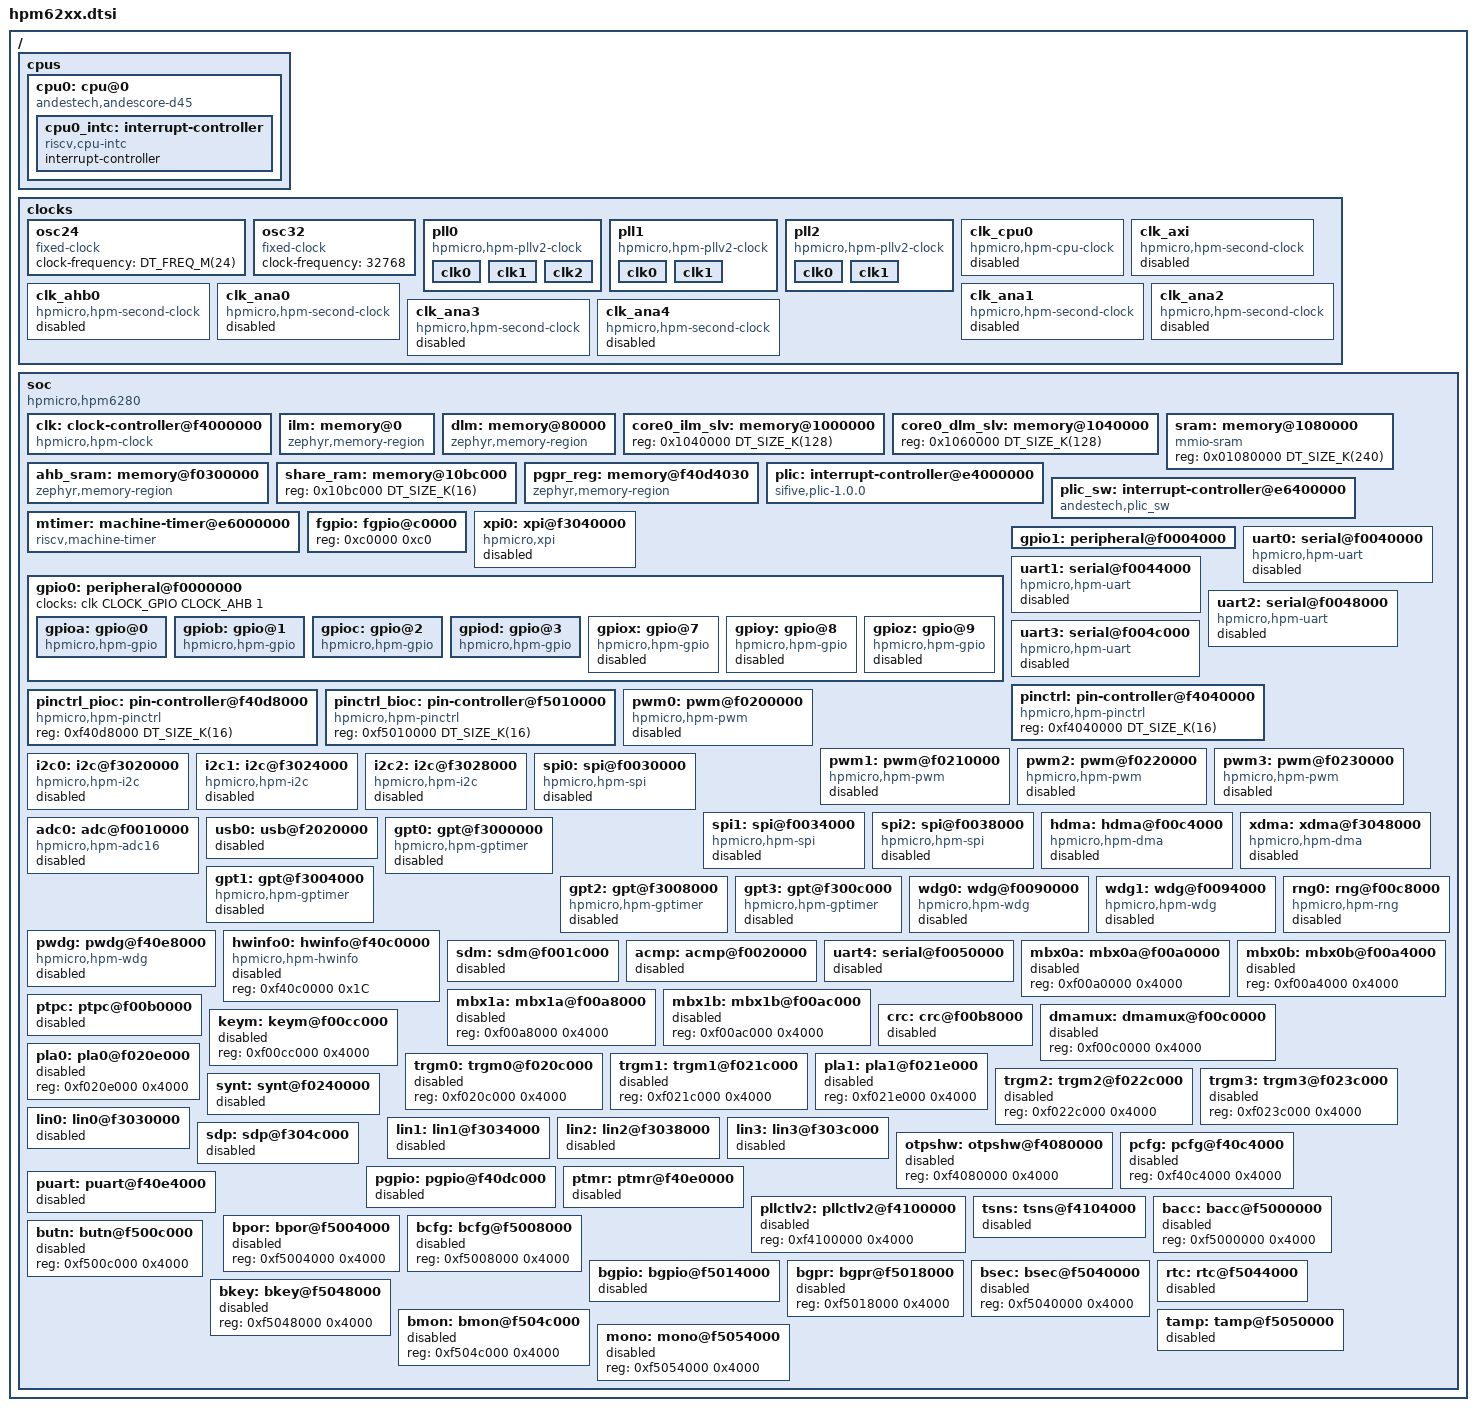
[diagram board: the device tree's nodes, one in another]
/*
* Copyright 2023-2026 HPMicro
* SPDX-License-Identifier: Apache-2.0
*/

/dts-v1/;
#include <zephyr/dt-bindings/gpio/gpio.h>
#include <zephyr/dt-bindings/i2c/i2c.h>
#include <zephyr/dt-bindings/pwm/pwm.h>
#include <dt-bindings/pwm/hpmicro-pwm-common.h>
#include <mem.h>
#include <freq.h>

/ {
	#address-cells = <1>;
	#size-cells = <1>;
	cpus {
		#address-cells = <1>;
		#size-cells = <0>;
		cpu0: cpu@0 {
			compatible = "andestech,andescore-d45", "riscv";
			reg = <0>;
			status = "okay";
			riscv,isa-base = "rv32i";
			riscv,isa-extensions = "i", "m", "a", "c", "f", "d", "b", "p", "zicsr", "zifencei",
				"xandes";
			i-cache-line-size = <64>;
			d-cache-line-size = <64>;
			cpu0_intc: interrupt-controller {
				compatible = "riscv,cpu-intc";
				#address-cells = <0>;
				#interrupt-cells = <1>;
				interrupt-controller;
			};
		};
	};

	clocks {
		osc24: osc24 {
			#clock-cells = <0>;
			compatible = "fixed-clock";
			clock-frequency = <DT_FREQ_M(24)>;
		};

		osc32: osc32 {
			#clock-cells = <0>;
			compatible = "fixed-clock";
			clock-frequency = <32768>;
		};

		pll0: pll0 {
			#clock-cells = <2>;
			compatible = "hpmicro,hpm-pllv2-clock";
			pll-frequency = <DT_FREQ_M(400)>;
			pll-index = <0>;
			clk0 {
				src-name = <CLK_SRC_PLL0_CLK0>;
				div-i = <0>;
				div-p = <0>;
			};

			clk1 {
				src-name = <CLK_SRC_PLL0_CLK1>;
				div-i = <1>;
				div-p = <1>;
			};

			clk2 {
				src-name = <CLK_SRC_PLL0_CLK2>;
				div-i = <2>;
				div-p = <3>;
			};
		};

		pll1: pll1 {
			#clock-cells = <2>;
			compatible = "hpmicro,hpm-pllv2-clock";
			pll-frequency = <DT_FREQ_M(576)>;
			pll-index = <1>;
			clk0 {
				src-name = <CLK_SRC_PLL1_CLK0>;
				div-i = <0>;
				div-p = <1>;
			};

			clk1 {
				src-name = <CLK_SRC_PLL1_CLK1>;
				div-i = <1>;
				div-p = <4>;
			};
		};

		pll2: pll2 {
			#clock-cells = <2>;
			compatible = "hpmicro,hpm-pllv2-clock";
			pll-frequency = <722534400>;
			pll-index = <2>;
			clk0 {
				src-name = <CLK_SRC_PLL2_CLK0>;
				div-i = <0>;
				div-p = <2>;
			};

			clk1 {
				src-name = <CLK_SRC_PLL2_CLK1>;
				div-i = <1>;
				div-p = <3>;
			};
		};

		clk_cpu0: clk_cpu0 {
			#clock-cells = <0>;
			compatible = "hpmicro,hpm-cpu-clock";
			node-name = <CLOCK_CPU0>;
			clocks = <&pll0 0 1>;
			axi-divider = <2>;
			ahb-divider = <2>;
			status = "disabled";
		};

		clk_axi: clk_axi {
			#clock-cells = <0>;
			compatible = "hpmicro,hpm-second-clock";
			node-name = <CLOCK_AXI>;
			clocks = <&clk_cpu0>;
			status = "disabled";
		};

		clk_ahb0: clk_ahb0 {
			#clock-cells = <0>;
			compatible = "hpmicro,hpm-second-clock";
			node-name = <CLOCK_AHB>;
			clocks = <&clk_cpu0>;
			status = "disabled";
		};

		clk_ana0: clk_ana0 {
			#clock-cells = <0>;
			compatible = "hpmicro,hpm-second-clock";
			node-name = <CLOCK_ANA0>;
			clocks = <&pll0 0 2>;
			status = "disabled";
		};

		clk_ana1: clk_ana1 {
			#clock-cells = <0>;
			compatible = "hpmicro,hpm-second-clock";
			node-name = <CLOCK_ANA1>;
			clocks = <&pll0 0 2>;
			status = "disabled";
		};

		clk_ana2: clk_ana2 {
			#clock-cells = <0>;
			compatible = "hpmicro,hpm-second-clock";
			node-name = <CLOCK_ANA2>;
			clocks = <&pll0 0 2>;
			status = "disabled";
		};

		clk_ana3: clk_ana3 {
			#clock-cells = <0>;
			compatible = "hpmicro,hpm-second-clock";
			node-name = <CLOCK_ANA3>;
			clocks = <&pll0 0 2>;
			status = "disabled";
		};

		clk_ana4: clk_ana4 {
			#clock-cells = <0>;
			compatible = "hpmicro,hpm-second-clock";
			node-name = <CLOCK_ANA4>;
			clocks = <&pll0 0 2>;
			status = "disabled";
		};
	};

	soc {
		#address-cells = <1>;
		#size-cells = <1>;
		compatible = "hpmicro,hpm6280";
		ranges;
		clk: clock-controller@f4000000 {
			compatible = "hpmicro,hpm-clock";
			reg = <0xf4000000 DT_SIZE_K(256)
				0xf4100000 DT_SIZE_K(16)>;
			reg-names = "sysctl", "pllv2";
			status = "okay";
			#clock-cells = <3>;
		};

		ilm: memory@0 {
			compatible = "zephyr,memory-region";
			reg = <0x0 DT_SIZE_K(128)>;
			zephyr,memory-region = "ITCM";
		};

		dlm: memory@80000 {
			compatible = "zephyr,memory-region";
			reg = <0x080000 DT_SIZE_K(128)>;
			zephyr,memory-region = "DTCM";
		};

		core0_ilm_slv: memory@1000000 {
			reg = <0x1040000 DT_SIZE_K(128)>;
		};

		core0_dlm_slv: memory@1040000 {
			reg = <0x1060000 DT_SIZE_K(128)>;
		};

		sram: memory@1080000 {
			compatible = "mmio-sram";
			reg = <0x01080000 DT_SIZE_K(240)>;
		};

		ahb_sram: memory@f0300000 {
			compatible = "zephyr,memory-region";
			reg = <0xf0300000 DT_SIZE_K(32)>;
			zephyr,memory-region = "AHB_SRAM";
		};

		share_ram: memory@10bc000 {
			reg = <0x10bc000 DT_SIZE_K(16)>;
		};

		pgpr_reg: memory@f40d4030 {
			compatible = "zephyr,memory-region";
			reg = <0xf40d4030 16>;
			zephyr,memory-region = "PGPR_REG";
		};

		plic: interrupt-controller@e4000000 {
			compatible = "sifive,plic-1.0.0";
			#address-cells = <1>;
			#interrupt-cells = <2>;
			interrupt-controller;
			reg = <    0xe4000000 0x00001000
				0xe4002000 0x00000800
				0xe4200000 0x00010000 >;
			reg-names = "prio", "irq_en", "reg";
			riscv,max-priority = <7>;
			riscv,ndev = <94>;
			interrupts-extended = <&cpu0_intc 11>;
		};

		plic_sw: interrupt-controller@e6400000 {
			compatible = "andestech,plic_sw";
			#address-cells = <1>;
			#interrupt-cells = <2>;
			interrupt-controller;
			reg = <0xe6400000 0x00400000>;
			interrupts-extended = <&cpu0_intc 3>;
		};

		mtimer: machine-timer@e6000000 {
			compatible = "riscv,machine-timer";
			clocks = <&clk CLOCK_MCHTMR0 CLK_SRC_OSC24M 1>;
			reg = <0xe6000000 0x8
				0xe6000008 0x8>;
			reg-names = "mtime", "mtimecmp";
			interrupts-extended = <&cpu0_intc 7>;
		};

		fgpio: fgpio@c0000 {
			reg = <0xc0000 0xc0>;
		};

		xpi0: xpi@f3040000 {
			compatible = "hpmicro,xpi";
			reg = <0xf3040000 DT_SIZE_K(16)>;
			clocks = <&clk CLOCK_XPI0 CLK_SRC_PLL0_CLK1 2>;
			#address-cells = <1>;
			#size-cells = <1>;
			status = "disabled";
		};

		gpio0: peripheral@f0000000 {
			#address-cells = <1>;
			#size-cells = <1>;
			ranges = <0x0 0xf0000000 DT_SIZE_K(16)>;
			clocks = <&clk CLOCK_GPIO CLOCK_AHB 1>;
		};

		gpio1: peripheral@f0004000 {
			#address-cells = <1>;
			#size-cells = <1>;
			ranges = <0x0 0xf0004000 DT_SIZE_K(16)>;
		};

		uart0: serial@f0040000 {
			compatible = "hpmicro,hpm-uart";
			reg = <0xf0040000 DT_SIZE_K(16)>;
			interrupts = <29 1>, <51 1>;
			interrupt-names = "uart", "idletimer";
			clocks = <&clk CLOCK_UART0 CLK_SRC_PLL1_CLK0 6>;
			interrupt-parent = <&plic>;
			status = "disabled";
		};

		uart1: serial@f0044000 {
			compatible = "hpmicro,hpm-uart";
			reg = <0xf0044000 DT_SIZE_K(16)>;
			interrupts = <30 1>, <51 1>;
			interrupt-names = "uart", "idletimer";
			clocks = <&clk CLOCK_UART1 CLK_SRC_PLL1_CLK0 6>;
			interrupt-parent = <&plic>;
			status = "disabled";
		};

		uart2: serial@f0048000 {
			compatible = "hpmicro,hpm-uart";
			reg = <0xf0048000 DT_SIZE_K(16)>;
			interrupts = <31 1>, <51 1>;
			interrupt-names = "uart", "idletimer";
			clocks = <&clk CLOCK_UART2 CLK_SRC_PLL1_CLK0 6>;
			interrupt-parent = <&plic>;
			status = "disabled";
		};

		uart3: serial@f004c000 {
			compatible = "hpmicro,hpm-uart";
			reg = <0xf004c000 DT_SIZE_K(16)>;
			interrupts = <32 1>, <51 1>;
			interrupt-names = "uart", "idletimer";
			clocks = <&clk CLOCK_UART3 CLK_SRC_PLL1_CLK0 6>;
			interrupt-parent = <&plic>;
			status = "disabled";
		};

		pinctrl: pin-controller@f4040000 {
			compatible = "hpmicro,hpm-pinctrl";
			reg = <0xf4040000 DT_SIZE_K(16)>;
			status = "okay";
		};

		pinctrl_pioc: pin-controller@f40d8000 {
			compatible = "hpmicro,hpm-pinctrl";
			reg = <0xf40d8000 DT_SIZE_K(16)>;
			status = "okay";
		};

		pinctrl_bioc: pin-controller@f5010000 {
			compatible = "hpmicro,hpm-pinctrl";
			reg = <0xf5010000 DT_SIZE_K(16)>;
			status = "okay";
		};

		pwm0: pwm@f0200000 {
			compatible = "hpmicro,hpm-pwm";
			reg = <0xf0200000 DT_SIZE_K(16)>;
			clocks = <&clk CLOCK_MOT0 CLOCK_AHB 1>;
			status = "disabled";
			#pwm-cells = <3>;
		};

		pwm1: pwm@f0210000 {
			compatible = "hpmicro,hpm-pwm";
			reg = <0xf0210000 DT_SIZE_K(16)>;
			clocks = <&clk CLOCK_MOT1 CLOCK_AHB 1>;
			status = "disabled";
			#pwm-cells = <3>;
		};

		pwm2: pwm@f0220000 {
			compatible = "hpmicro,hpm-pwm";
			reg = <0xf0220000 DT_SIZE_K(16)>;
			clocks = <&clk CLOCK_MOT2 CLOCK_AHB 1>;
			status = "disabled";
			#pwm-cells = <3>;
		};

		pwm3: pwm@f0230000 {
			compatible = "hpmicro,hpm-pwm";
			reg = <0xf0230000 DT_SIZE_K(16)>;
			clocks = <&clk CLOCK_MOT3 CLOCK_AHB 1>;
			status = "disabled";
			#pwm-cells = <3>;
		};

		i2c0: i2c@f3020000 {
			compatible = "hpmicro,hpm-i2c";
			#address-cells = <1>;
			#size-cells = <0>;
			clocks = <&clk CLOCK_I2C0 CLK_SRC_PLL1_CLK0 6>;
			clock-frequency = <I2C_BITRATE_STANDARD>;
			reg = <0xf3020000 DT_SIZE_K(16)>;
			interrupts = <53 1>;
			interrupt-parent = <&plic>;
			status = "disabled";
		};

		i2c1: i2c@f3024000 {
			compatible = "hpmicro,hpm-i2c";
			#address-cells = <1>;
			#size-cells = <0>;
			clocks = <&clk CLOCK_I2C1 CLK_SRC_PLL1_CLK0 6>;
			clock-frequency = <I2C_BITRATE_STANDARD>;
			reg = <0xf3024000 DT_SIZE_K(16)>;
			interrupts = <54 1>;
			interrupt-parent = <&plic>;
			status = "disabled";
		};

		i2c2: i2c@f3028000 {
			compatible = "hpmicro,hpm-i2c";
			#address-cells = <1>;
			#size-cells = <0>;
			clocks = <&clk CLOCK_I2C2 CLK_SRC_PLL1_CLK0 6>;
			clock-frequency = <I2C_BITRATE_STANDARD>;
			reg = <0xf3028000 DT_SIZE_K(16)>;
			interrupts = <55 1>;
			interrupt-parent = <&plic>;
			status = "disabled";
		};

		spi0: spi@f0030000 {
			compatible = "hpmicro,hpm-spi";
			reg = <0xf0030000 DT_SIZE_K(16)>;
			clocks = <&clk CLOCK_SPI0 CLK_SRC_PLL1_CLK0 6>;
			interrupts = <25 1>;
			interrupt-parent = <&plic>;
			status = "disabled";
			#address-cells = <1>;
			#size-cells = <0>;
			cs-sck-delay = <3>;
			cs-minimum-high-time = <11>;
		};

		spi1: spi@f0034000 {
			compatible = "hpmicro,hpm-spi";
			reg = <0xf0034000 DT_SIZE_K(16)>;
			clocks = <&clk CLOCK_SPI1 CLK_SRC_PLL1_CLK0 6>;
			interrupts = <26 1>;
			interrupt-parent = <&plic>;
			status = "disabled";
			#address-cells = <1>;
			#size-cells = <0>;
			cs-sck-delay = <3>;
			cs-minimum-high-time = <11>;
		};

		spi2: spi@f0038000 {
			compatible = "hpmicro,hpm-spi";
			reg = <0xf0038000 DT_SIZE_K(16)>;
			clocks = <&clk CLOCK_SPI2 CLK_SRC_PLL1_CLK0 6>;
			interrupts = <27 1>;
			interrupt-parent = <&plic>;
			status = "disabled";
			#address-cells = <1>;
			#size-cells = <0>;
			cs-sck-delay = <3>;
			cs-minimum-high-time = <11>;
		};

		hdma: hdma@f00c4000 {
			#dma-cells = <2>;
			compatible = "hpmicro,hpm-dma";
			dma-channels = <8>;
			dma-requests = <68>;
			reg = <0xf00c4000 DT_SIZE_K(16)>,
				<0xf00c0000 DT_SIZE_K(16)>; /* DMAMUX base */
				interrupts = <72 1>;
			interrupt-parent = <&plic>;
			clocks = <&clk CLOCK_HDMA CLOCK_AHB 1>;
			status = "disabled";
		};

		xdma: xdma@f3048000 {
			#dma-cells = <2>;
			compatible = "hpmicro,hpm-dma";
			dma-channels = <8>;
			dma-requests = <68>;
			reg = <0xf3048000 DT_SIZE_K(16)>,
				<0xf00c0000 DT_SIZE_K(16)>; /* DMAMUX base */
				interrupts = <71 1>;
			interrupt-parent = <&plic>;
			clocks = <&clk CLOCK_XDMA CLOCK_AXI 1>;
			status = "disabled";
		};

		adc0: adc@f0010000 {
			compatible = "hpmicro,hpm-adc16";
			reg = <0xf0010000 DT_SIZE_K(16)>;
			interrupts = <15 1>;
			interrupt-parent = <&plic>;
			clocks = <&clk CLOCK_ADC0 CLK_ADC_SRC_ANA0 1>,
				<&clk CLOCK_ANA0 CLK_SRC_PLL0_CLK0 2>;
			adc-clk-div = <4>;
			sample-time = <20>;
			status = "disabled";
			#io-channel-cells = <1>;
		};

		usb0: usb@f2020000 {
			clk-name = <CLOCK_USB0>;
			reg = <0xf2020000 DT_SIZE_K(16)>;
			interrupts = <74 1>;
			interrupt-parent = <&plic>;
			clocks = <&clk CLOCK_USB0 CLOCK_AXI 1>;
			num-bidir-endpoints = <8>;
			status = "disabled";
		};

		gpt0: gpt@f3000000 {
			compatible = "hpmicro,hpm-gptimer";
			reg = <0xf3000000 0x4000>;
			interrupts = <49 1>;
			interrupt-parent = <&plic>;
			gptfreq = <100000000>;
			clocks = <&clk CLOCK_GPTMR0 CLK_SRC_PLL0_CLK0 4>;
			status = "disabled";
		};

		gpt1: gpt@f3004000 {
			compatible = "hpmicro,hpm-gptimer";
			reg = <0xf3004000 0x4000>;
			interrupts = <50 1>;
			interrupt-parent = <&plic>;
			gptfreq = <100000000>;
			clocks = <&clk CLOCK_GPTMR1 CLK_SRC_PLL0_CLK0 4>;
			status = "disabled";
		};

		gpt2: gpt@f3008000 {
			compatible = "hpmicro,hpm-gptimer";
			reg = <0xf3008000 0x4000>;
			interrupts = <51 1>;
			interrupt-parent = <&plic>;
			gptfreq = <100000000>;
			clocks = <&clk CLOCK_GPTMR2 CLK_SRC_PLL0_CLK0 4>;
			status = "disabled";
		};

		gpt3: gpt@f300c000 {
			compatible = "hpmicro,hpm-gptimer";
			reg = <0xf300c000 0x4000>;
			interrupts = <52 1>;
			interrupt-parent = <&plic>;
			gptfreq = <100000000>;
			clocks = <&clk CLOCK_GPTMR3 CLK_SRC_PLL0_CLK0 4>;
			status = "disabled";
		};

		wdg0: wdg@f0090000 {
			compatible = "hpmicro,hpm-wdg";
			reg = <0xf0090000 0x4000>;
			interrupts = <42 1>;
			interrupt-parent = <&plic>;
			clocks = <&clk CLOCK_WATCHDOG0 CLK_WDG_SRC_OSC32K 1>;
			status = "disabled";
		};

		wdg1: wdg@f0094000 {
			compatible = "hpmicro,hpm-wdg";
			reg = <0xf0094000 0x4000>;
			interrupts = <43 1>;
			interrupt-parent = <&plic>;
			clocks = <&clk CLOCK_WATCHDOG1 CLK_WDG_SRC_OSC32K 1>;
			status = "disabled";
		};

		pwdg: pwdg@f40e8000 {
			compatible = "hpmicro,hpm-wdg";
			reg = <0xf40e8000 0x4000>;
			interrupts = <77 1>;
			interrupt-parent = <&plic>;
			clocks = <&clk CLOCK_PWDG CLK_PWDG_SRC_OSC32K 1>;
			status = "disabled";
		};

		hwinfo0: hwinfo@f40c0000 {
			compatible = "hpmicro,hpm-hwinfo";
			reg = <0xf40c0000 0x1C>;
			status = "disabled";
		};

		rng0: rng@f00c8000 {
			compatible = "hpmicro,hpm-rng";
			clk-name = <CLOCK_RNG>;
			clk-source = <0>;
			clk-divider = <0>;
			reg = <0xf00c8000 0x4000>;
			interrupts = <73 1>;
			interrupt-parent = <&plic>;
			clocks = <&clk CLOCK_RNG CLOCK_AHB 1>;
			status = "disabled";
		};

		sdm: sdm@f001c000 {
			reg = <0xf001c000 0x4000>;
			clocks = <&clk CLOCK_SDM0 CLOCK_AHB 1>;
			status = "disabled";
		};

		acmp: acmp@f0020000 {
			reg = <0xf0020000 0x4000>;
			clocks = <&clk CLOCK_ACMP0 CLOCK_AHB 1>;
			status = "disabled";
		};

		uart4: serial@f0050000 {
			reg = <0xf0050000 0x4000>;
			clocks = <&clk CLOCK_UART4 CLK_SRC_PLL1_CLK0 6>;
			status = "disabled";
		};

		mbx0a: mbx0a@f00a0000 {
			reg = <0xf00a0000 0x4000>;
			status = "disabled";
		};

		mbx0b: mbx0b@f00a4000 {
			reg = <0xf00a4000 0x4000>;
			status = "disabled";
		};

		mbx1a: mbx1a@f00a8000 {
			reg = <0xf00a8000 0x4000>;
			status = "disabled";
		};

		mbx1b: mbx1b@f00ac000 {
			reg = <0xf00ac000 0x4000>;
			status = "disabled";
		};

		ptpc: ptpc@f00b0000 {
			reg = <0xf00b0000 0x4000>;
			clocks = <&clk CLOCK_PTPC CLK_SRC_PLL0_CLK0 4>;
			status = "disabled";
		};

		crc: crc@f00b8000 {
			reg = <0xf00b8000 0x4000>;
			clocks = <&clk CLOCK_CRC0 CLOCK_AHB 1>;
			status = "disabled";
		};

		dmamux: dmamux@f00c0000 {
			reg = <0xf00c0000 0x4000>;
			status = "disabled";
		};

		keym: keym@f00cc000 {
			reg = <0xf00cc000 0x4000>;
			status = "disabled";
		};

		trgm0: trgm0@f020c000 {
			reg = <0xf020c000 0x4000>;
			status = "disabled";
		};

		pla0: pla0@f020e000 {
			reg = <0xf020e000 0x4000>;
			status = "disabled";
		};

		trgm1: trgm1@f021c000 {
			reg = <0xf021c000 0x4000>;
			status = "disabled";
		};

		pla1: pla1@f021e000 {
			reg = <0xf021e000 0x4000>;
			status = "disabled";
		};

		trgm2: trgm2@f022c000 {
			reg = <0xf022c000 0x4000>;
			status = "disabled";
		};

		trgm3: trgm3@f023c000 {
			reg = <0xf023c000 0x4000>;
			status = "disabled";
		};

		synt: synt@f0240000 {
			reg = <0xf0240000 0x4000>;
			clocks = <&clk CLOCK_SYNT CLOCK_AHB 1>;
			status = "disabled";
		};

		lin0: lin0@f3030000 {
			reg = <0xf3030000 0x4000>;
			clocks = <&clk CLOCK_LIN0 CLK_SRC_PLL1_CLK0 6>;
			status = "disabled";
		};

		lin1: lin1@f3034000 {
			reg = <0xf3034000 0x4000>;
			clocks = <&clk CLOCK_LIN1 CLK_SRC_PLL1_CLK0 6>;
			status = "disabled";
		};

		lin2: lin2@f3038000 {
			reg = <0xf3038000 0x4000>;
			clocks = <&clk CLOCK_LIN2 CLK_SRC_PLL1_CLK0 6>;
			status = "disabled";
		};

		lin3: lin3@f303c000 {
			reg = <0xf303c000 0x4000>;
			clocks = <&clk CLOCK_LIN3 CLK_SRC_PLL1_CLK0 6>;
			status = "disabled";
		};

		sdp: sdp@f304c000 {
			reg = <0xf304c000 0x4000>;
			clocks = <&clk CLOCK_SDP CLOCK_AXI 1>;
			status = "disabled";
		};

		otpshw: otpshw@f4080000 {
			reg = <0xf4080000 0x4000>;
			status = "disabled";
		};

		pcfg: pcfg@f40c4000 {
			reg = <0xf40c4000 0x4000>;
			status = "disabled";
		};

		pgpio: pgpio@f40dc000 {
			reg = <0xf40dc000 0x4000>;
			clocks = <&osc24>;
			status = "disabled";
		};

		ptmr: ptmr@f40e0000 {
			reg = <0xf40e0000 0x4000>;
			clocks = <&clk CLOCK_PTMR CLK_SRC_OSC24M 1>;
			status = "disabled";
		};

		puart: puart@f40e4000 {
			reg = <0xf40e4000 0x4000>;
			clocks = <&clk CLOCK_PUART CLK_SRC_OSC24M 1>;
			status = "disabled";
		};

		pllctlv2: pllctlv2@f4100000 {
			reg = <0xf4100000 0x4000>;
			status = "disabled";
		};

		tsns: tsns@f4104000 {
			reg = <0xf4104000 0x4000>;
			clocks = <&clk CLOCK_TSNS CLOCK_CPU0 1>;
			status = "disabled";
		};

		bacc: bacc@f5000000 {
			reg = <0xf5000000 0x4000>;
			status = "disabled";
		};

		bpor: bpor@f5004000 {
			reg = <0xf5004000 0x4000>;
			status = "disabled";
		};

		bcfg: bcfg@f5008000 {
			reg = <0xf5008000 0x4000>;
			status = "disabled";
		};

		butn: butn@f500c000 {
			reg = <0xf500c000 0x4000>;
			status = "disabled";
		};

		bgpio: bgpio@f5014000 {
			reg = <0xf5014000 0x4000>;
			clocks = <&osc32>;
			status = "disabled";
		};

		bgpr: bgpr@f5018000 {
			reg = <0xf5018000 0x4000>;
			status = "disabled";
		};

		bsec: bsec@f5040000 {
			reg = <0xf5040000 0x4000>;
			status = "disabled";
		};

		rtc: rtc@f5044000 {
			reg = <0xf5044000 0x4000>;
			clocks = <&osc32>;
			status = "disabled";
		};

		bkey: bkey@f5048000 {
			reg = <0xf5048000 0x4000>;
			status = "disabled";
		};

		bmon: bmon@f504c000 {
			reg = <0xf504c000 0x4000>;
			status = "disabled";
		};

		tamp: tamp@f5050000 {
			reg = <0xf5050000 0x4000>;
			clocks = <&osc32>;
			status = "disabled";
		};

		mono: mono@f5054000 {
			reg = <0xf5054000 0x4000>;
			status = "disabled";
		};
	};
};

&gpio0 {
	gpioa: gpio@0 {
		compatible = "hpmicro,hpm-gpio";
		reg = <0x0 DT_SIZE_K(16)>;
		gpio-controller;
		#gpio-cells = <2>;
		hpmicro-gpio-port = <0>;
		interrupts = <1 1>;
		interrupt-parent = <&plic>;
	};

	gpiob: gpio@1 {
		compatible = "hpmicro,hpm-gpio";
		reg = <0x0 DT_SIZE_K(16)>;
		gpio-controller;
		#gpio-cells = <2>;
		hpmicro-gpio-port = <1>;
		interrupts = <2 1>;
		interrupt-parent = <&plic>;
	};

	gpioc: gpio@2 {
		compatible = "hpmicro,hpm-gpio";
		reg = <0x0 DT_SIZE_K(16)>;
		gpio-controller;
		#gpio-cells = <2>;
		hpmicro-gpio-port = <2>;
		interrupts = <3 1>;
		interrupt-parent = <&plic>;
	};

	gpiod: gpio@3 {
		compatible = "hpmicro,hpm-gpio";
		reg = <0x0 DT_SIZE_K(16)>;
		gpio-controller;
		#gpio-cells = <2>;
		hpmicro-gpio-port = <3>;
		interrupts = <4 1>;
		interrupt-parent = <&plic>;
	};

	gpiox: gpio@7 {
		compatible = "hpmicro,hpm-gpio";
		reg = <0x0 DT_SIZE_K(16)>;
		gpio-controller;
		#gpio-cells = <2>;
		hpmicro-gpio-port = <13>;
		interrupt-parent = <&plic>;
		interrupts = <5 1>;
		status = "disabled";
	};

	gpioy: gpio@8 {
		compatible = "hpmicro,hpm-gpio";
		reg = <0x0 DT_SIZE_K(16)>;
		gpio-controller;
		#gpio-cells = <2>;
		hpmicro-gpio-port = <14>;
		interrupts = <6 1>;
		interrupt-parent = <&plic>;
		status = "disabled";
	};

	gpioz: gpio@9 {
		compatible = "hpmicro,hpm-gpio";
		reg = <0x0 DT_SIZE_K(16)>;
		gpio-controller;
		#gpio-cells = <2>;
		hpmicro-gpio-port = <15>;
		interrupts = <7 1>;
		interrupt-parent = <&plic>;
		status = "disabled";
	};
};
